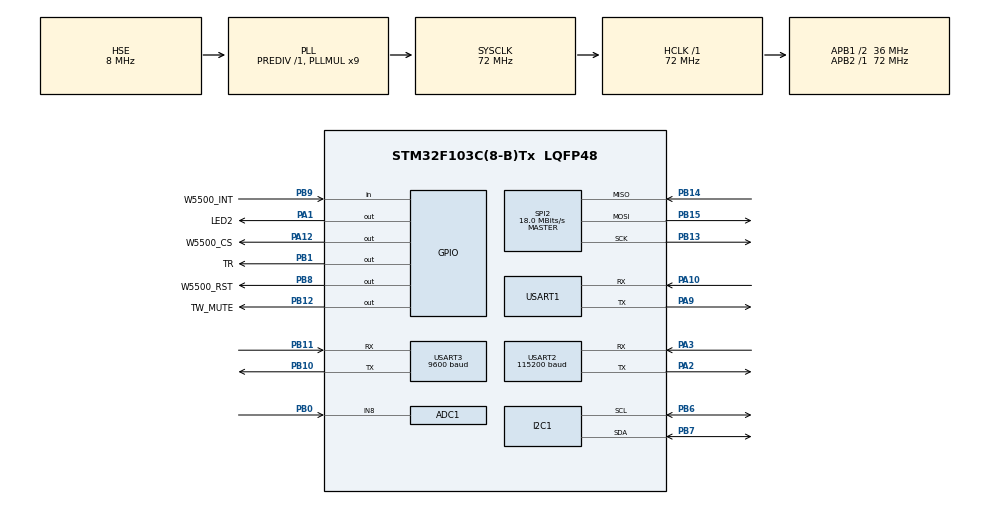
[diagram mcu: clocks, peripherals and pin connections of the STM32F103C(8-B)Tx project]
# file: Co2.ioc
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ADC1.Channel-0\#ChannelRegularConversion=ADC_CHANNEL_8
ADC1.ContinuousConvMode=ENABLE
ADC1.NbrOfConversion=1
ADC1.NbrOfConversionFlag=1
ADC1.Rank-0\#ChannelRegularConversion=1
ADC1.SamplingTime-0\#ChannelRegularConversion=ADC_SAMPLETIME_1CYCLE_5
ADC1.master=1
Dma.ADC1.0.Direction=DMA_PERIPH_TO_MEMORY
Dma.ADC1.0.Instance=DMA1_Channel1
Dma.ADC1.0.MemDataAlignment=DMA_MDATAALIGN_HALFWORD
Dma.ADC1.0.MemInc=DMA_MINC_ENABLE
Dma.ADC1.0.Mode=DMA_CIRCULAR
Dma.ADC1.0.PeriphDataAlignment=DMA_PDATAALIGN_HALFWORD
Dma.ADC1.0.PeriphInc=DMA_PINC_DISABLE
Dma.ADC1.0.Priority=DMA_PRIORITY_LOW
Dma.Request0=ADC1
I2C1.I2C_Mode=I2C_Fast
Mcu.Family=STM32F1
Mcu.Name=STM32F103C(8-B)Tx
Mcu.Package=LQFP48
NVIC.PriorityGroup=NVIC_PRIORITYGROUP_4
NVIC.TIM1_UP_IRQn=true\:15\:0\:false\:false\:true\:false\:true\:true
NVIC.TimeBase=TIM1_UP_IRQn
NVIC.TimeBaseIP=TIM1
NVIC.USART2_IRQn=true\:0\:0\:false\:false\:true\:true\:true\:true
PA1.GPIO_Label=LED2
PA1.GPIO_Speed=GPIO_SPEED_FREQ_HIGH
PA1.PinState=GPIO_PIN_SET
PA1.Signal=GPIO_Output
PA10.Mode=Asynchronous
PA10.Signal=USART1_RX
PA12.GPIO_Label=W5500_CS
PA12.GPIO_Speed=GPIO_SPEED_FREQ_HIGH
PA12.PinState=GPIO_PIN_SET
PA12.Signal=GPIO_Output
PA13.Mode=Serial_Wire
PA13.Signal=SYS_JTMS-SWDIO
PA14.Mode=Serial_Wire
PA14.Signal=SYS_JTCK-SWCLK
PA2.Mode=Asynchronous
PA2.Signal=USART2_TX
PA3.Mode=Asynchronous
PA3.Signal=USART2_RX
PA9.Mode=Asynchronous
PA9.Signal=USART1_TX
PB0.Signal=ADCx_IN8
PB1.GPIO_Label=TR
PB1.GPIO_Speed=GPIO_SPEED_FREQ_HIGH
PB1.Signal=GPIO_Output
PB10.Mode=Asynchronous
PB10.Signal=USART3_TX
PB11.Mode=Asynchronous
PB11.Signal=USART3_RX
PB12.GPIO_Label=TW_MUTE
PB12.GPIO_Speed=GPIO_SPEED_FREQ_HIGH
PB12.Signal=GPIO_Output
PB13.Mode=Full_Duplex_Master
PB13.Signal=SPI2_SCK
PB14.Mode=Full_Duplex_Master
PB14.Signal=SPI2_MISO
PB15.Mode=Full_Duplex_Master
PB15.Signal=SPI2_MOSI
PB6.Mode=I2C
PB6.Signal=I2C1_SCL
PB7.Mode=I2C
PB7.Signal=I2C1_SDA
PB8.GPIO_Label=W5500_RST
PB8.GPIO_Speed=GPIO_SPEED_FREQ_HIGH
PB8.PinState=GPIO_PIN_SET
PB8.Signal=GPIO_Output
PB9.GPIO_Label=W5500_INT
PB9.GPIO_PuPd=GPIO_PULLUP
PB9.Signal=GPIO_Input
PC14-OSC32_IN.Mode=LSE-External-Oscillator
PC14-OSC32_IN.Signal=RCC_OSC32_IN
PC15-OSC32_OUT.Mode=LSE-External-Oscillator
PC15-OSC32_OUT.Signal=RCC_OSC32_OUT
PD0-OSC_IN.Mode=HSE-External-Oscillator
PD0-OSC_IN.Signal=RCC_OSC_IN
PD1-OSC_OUT.Mode=HSE-External-Oscillator
PD1-OSC_OUT.Signal=RCC_OSC_OUT
ProjectManager.HeapSize=0x200
ProjectManager.StackSize=0x400
ProjectManager.TargetToolchain=MDK-ARM V5.32
RCC.ADCPresc=RCC_ADCPCLK2_DIV6
RCC.AHBFreq_Value=72000000
RCC.APB1CLKDivider=RCC_HCLK_DIV2
RCC.APB1Freq_Value=36000000
RCC.APB1TimFreq_Value=72000000
RCC.APB2Freq_Value=72000000
RCC.APB2TimFreq_Value=72000000
RCC.HCLKFreq_Value=72000000
RCC.PLLMUL=RCC_PLL_MUL9
RCC.PLLSourceVirtual=RCC_PLLSOURCE_HSE
RCC.SYSCLKFreq_VALUE=72000000
RCC.SYSCLKSource=RCC_SYSCLKSOURCE_PLLCLK
RCC.USBFreq_Value=72000000
SH.ADCx_IN8.0=ADC1_IN8,IN8
SPI2.BaudRatePrescaler=SPI_BAUDRATEPRESCALER_2
SPI2.CalculateBaudRate=18.0 MBits/s
SPI2.Direction=SPI_DIRECTION_2LINES
SPI2.Mode=SPI_MODE_MASTER
SPI2.VirtualType=VM_MASTER
USART1.VirtualMode=VM_ASYNC
USART2.BaudRate=115200
USART2.VirtualMode=VM_ASYNC
USART3.BaudRate=9600
USART3.VirtualMode=VM_ASYNC
VP_SYS_VS_tim1.Mode=TIM1
board=custom

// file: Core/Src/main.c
/* USER CODE BEGIN Header */
/**
  ******************************************************************************
  * @file           : main.c
  * @brief          : Main program body
  ******************************************************************************
  * @attention
  *
  * Copyright (c) 2024 STMicroelectronics.
  * All rights reserved.
  *
  * This software is licensed under terms that can be found in the LICENSE file
  * in the root directory of this software component.
  * If no LICENSE file comes with this software, it is provided AS-IS.
  *
  ******************************************************************************
  */
  /* USER CODE END Header */
  /* Includes ------------------------------------------------------------------*/
#include "main.h"
#include "adc.h"
#include "dma.h"
#include "i2c.h"
#include "spi.h"
#include "usart.h"
#include "gpio.h"

/* USER CODE BEGIN Includes */
#include "App_Com.h"
#include "App_Task.h"
#include "App_UI.h"
/* USER CODE END Includes */

void SystemClock_Config(void);

int main(void)
{

    /* MCU Configuration--------------------------------------------------------*/

    /* Reset of all peripherals, Initializes the Flash interface and the Systick. */
    HAL_Init();

    /* Configure the system clock */
    SystemClock_Config();

    /* Initialize all configured peripherals */
    MX_GPIO_Init();
    MX_DMA_Init();
    MX_USART1_UART_Init();
    MX_USART2_UART_Init();
    MX_SPI2_Init();
    MX_USART3_UART_Init();
    MX_ADC1_Init();
    MX_I2C1_Init();
    /* USER CODE BEGIN 2 */
    printf("hello");

    App_Com_Init();
    App_UI_Init();
    App_Task_Init();

    // testDrawXBM(&u8g2);
    // testDrawFrame(&u8g2);
    // testDrawProcess(&u8g2);
    // testDrawMulti(&u8g2);

    /* ------------以太网测试--------------- */
    // Inf_W5500_Init();
    // printf("初始化以太网成功...\r\n");
    // while (Inf_W5500_StartTcpClient() == 0) {
    //     HAL_Delay(1000);
    // }
    // printf("开启客户端成功....\r\n");
    // Inf_W5500_SendTcpData("hello world\r\n", 13);
    /* ------------以太网测试--------------- */

    /* ---------------RS485---------------------- */
    // Inf_RS485_Init();
    // uint8_t send_data[8] = { 0x01, 0x03, 0x00, 0x00, 0x00, 0x01 };
    // Inf_RS485_SendCmd(send_data, 8);
    /* ---------------RS485---------------------- */

  /* USER CODE END 2 */

  /* Infinite loop */
  /* USER CODE BEGIN WHILE */
    while (1) {
        // TW_ASRPRO_SendData("123", 3);
        // HAL_Delay(5000);

        // u8g2_DrawCircle(&u8g2, 64, 32, 30, U8G2_DRAW_ALL); //画空心圆
        // u8g2_SendBuffer(&u8g2);
        // u8g2_DrawBox(&u8g2, 0, 0, 20, 20); //画实心方形
        // u8g2_DrawBox(&u8g2, 20, 20, 20, 20);//画实心方形
        // u8g2_SendBuffer(&u8g2);
        // u8g2_DrawFrame(&u8g2, 10, 40, 20, 20);//画空心方形
        // u8g2_SendBuffer(&u8g2);
        // u8g2_SetFont(&u8g2, u8g2_font_DigitalDiscoThin_tf);//设置字体集
        // u8g2_DrawStr(&u8g2, 30, 10, "freertos");//绘制字符串
        // u8g2_SendBuffer(&u8g2);

        /*
        u8g2_FirstPage(&u8g2);
        do {
            draw(&u8g2);
            //	   u8g2DrawTest(&u8g2);

            //	   u8g2_DrawBox(&u8g2,0,0,20,20); //画实心方形
            //	   u8g2_DrawBox(&u8g2,20,20,20,20);//画实心方形
            //	   u8g2_DrawFrame(&u8g2,10,40,20,20);//画空心方形
            // u8g2_SetFont(&u8g2, u8g2_font_DigitalDiscoThin_tf);//设置字体集
            // u8g2_DrawStr(&u8g2, 30, 10, "freedom");//绘制字符串
        } while (u8g2_NextPage(&u8g2));
        HAL_Delay(1000);        */

        /* USER CODE END WHILE */

    }
}

void SystemClock_Config(void)
{
    RCC_OscInitTypeDef RCC_OscInitStruct = { 0 };
    RCC_ClkInitTypeDef RCC_ClkInitStruct = { 0 };
    RCC_PeriphCLKInitTypeDef PeriphClkInit = { 0 };

    /** Initializes the RCC Oscillators according to the specified parameters
    * in the RCC_OscInitTypeDef structure.
    */
    RCC_OscInitStruct.OscillatorType = RCC_OSCILLATORTYPE_HSE;
    RCC_OscInitStruct.HSEState = RCC_HSE_ON;
    RCC_OscInitStruct.HSEPredivValue = RCC_HSE_PREDIV_DIV1;
    RCC_OscInitStruct.HSIState = RCC_HSI_ON;
    RCC_OscInitStruct.PLL.PLLState = RCC_PLL_ON;
    RCC_OscInitStruct.PLL.PLLSource = RCC_PLLSOURCE_HSE;
    RCC_OscInitStruct.PLL.PLLMUL = RCC_PLL_MUL9;
    if (HAL_RCC_OscConfig(&RCC_OscInitStruct) != HAL_OK)
    {
        Error_Handler();
    }

    /** Initializes the CPU, AHB and APB buses clocks
    */
    RCC_ClkInitStruct.ClockType = RCC_CLOCKTYPE_HCLK | RCC_CLOCKTYPE_SYSCLK
        | RCC_CLOCKTYPE_PCLK1 | RCC_CLOCKTYPE_PCLK2;
    RCC_ClkInitStruct.SYSCLKSource = RCC_SYSCLKSOURCE_PLLCLK;
    RCC_ClkInitStruct.AHBCLKDivider = RCC_SYSCLK_DIV1;
    RCC_ClkInitStruct.APB1CLKDivider = RCC_HCLK_DIV2;
    RCC_ClkInitStruct.APB2CLKDivider = RCC_HCLK_DIV1;

    if (HAL_RCC_ClockConfig(&RCC_ClkInitStruct, FLASH_LATENCY_2) != HAL_OK)
    {
        Error_Handler();
    }
    PeriphClkInit.PeriphClockSelection = RCC_PERIPHCLK_ADC;
    PeriphClkInit.AdcClockSelection = RCC_ADCPCLK2_DIV6;
    if (HAL_RCCEx_PeriphCLKConfig(&PeriphClkInit) != HAL_OK)
    {
        Error_Handler();
    }
}

void HAL_TIM_PeriodElapsedCallback(TIM_HandleTypeDef* htim)
{
    if (htim->Instance == TIM1) {
        HAL_IncTick();
    }
}

void Error_Handler(void)
{
    __disable_irq();
    while (1)
    {
    }
}
